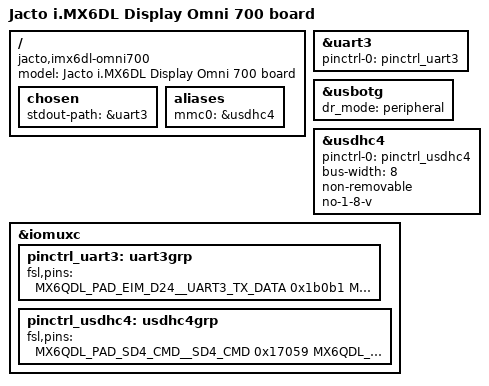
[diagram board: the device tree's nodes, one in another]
// SPDX-License-Identifier: (GPL-2.0+ OR MIT)

/dts-v1/;

#include <dt-bindings/gpio/gpio.h>
#include "imx6dl.dtsi"

/ {
	model = "Jacto i.MX6DL Display Omni 700 board";
	compatible = "jacto,imx6dl-omni700", "fsl,imx6dl";

	chosen {
		stdout-path = &uart3;
	};

	aliases {
		mmc0 = &usdhc4;
	};
};

&uart3 {
	pinctrl-names = "default";
	pinctrl-0 = <&pinctrl_uart3>;
	status = "okay";
};

&usbotg {
	dr_mode = "peripheral";
	status = "okay";
};

&usdhc4 {
	pinctrl-names = "default";
	pinctrl-0 = <&pinctrl_usdhc4>;
	bus-width = <8>;
	non-removable;
	no-1-8-v;
	status = "okay";
};

&iomuxc {
	pinctrl_uart3: uart3grp {
		fsl,pins = <
			MX6QDL_PAD_EIM_D24__UART3_TX_DATA	0x1b0b1
			MX6QDL_PAD_EIM_D25__UART3_RX_DATA	0x1b0b1
		>;
	};

	pinctrl_usdhc4: usdhc4grp {
		fsl,pins = <
			MX6QDL_PAD_SD4_CMD__SD4_CMD		0x17059
			MX6QDL_PAD_SD4_CLK__SD4_CLK		0x10059
			MX6QDL_PAD_SD4_DAT0__SD4_DATA0		0x17059
			MX6QDL_PAD_SD4_DAT1__SD4_DATA1		0x17059
			MX6QDL_PAD_SD4_DAT2__SD4_DATA2		0x17059
			MX6QDL_PAD_SD4_DAT3__SD4_DATA3		0x17059
			MX6QDL_PAD_SD4_DAT4__SD4_DATA4		0x17059
			MX6QDL_PAD_SD4_DAT5__SD4_DATA5		0x17059
			MX6QDL_PAD_SD4_DAT6__SD4_DATA6		0x17059
			MX6QDL_PAD_SD4_DAT7__SD4_DATA7		0x17059
		>;
	};
};
